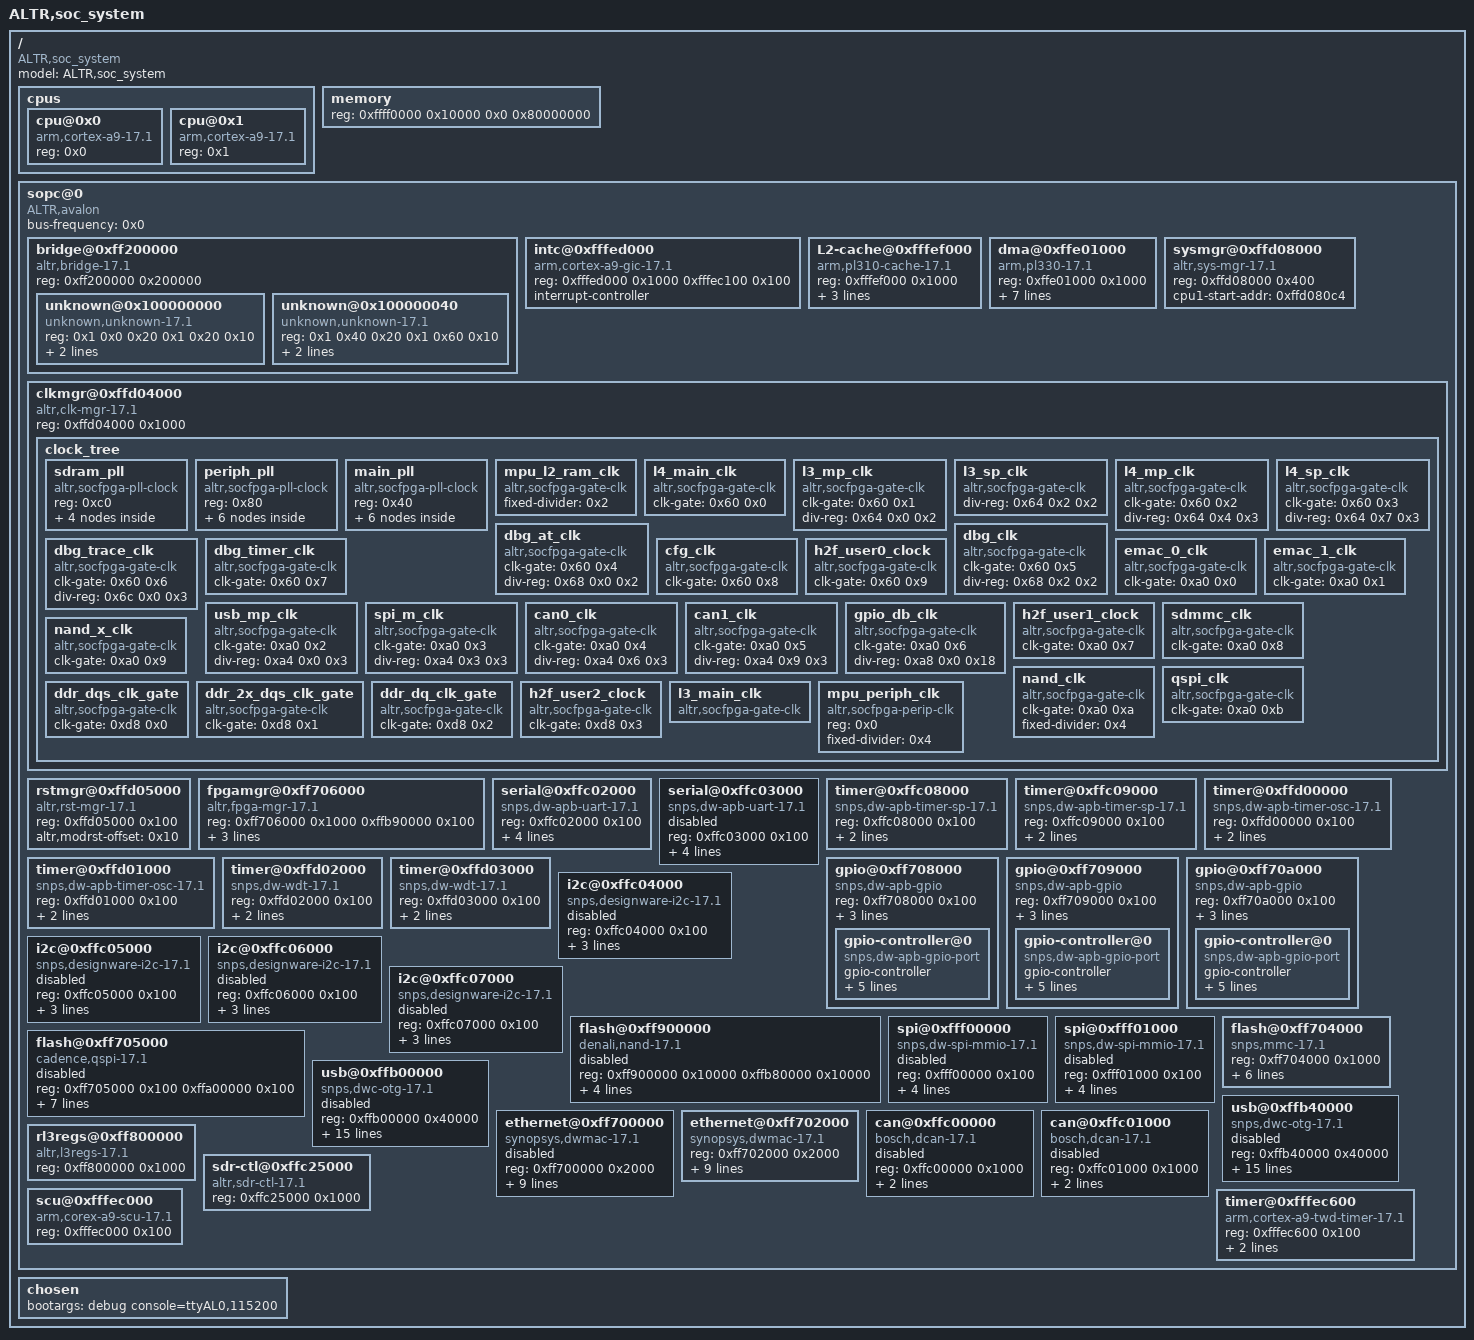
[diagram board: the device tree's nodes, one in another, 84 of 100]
/dts-v1/;

/ {
	model = "ALTR,soc_system";
	compatible = "ALTR,soc_system";
	#address-cells = <0x1>;
	#size-cells = <0x1>;

	cpus {
		#address-cells = <0x1>;
		#size-cells = <0x0>;

		cpu@0x0 {
			device_type = "cpu";
			compatible = "arm,cortex-a9-17.1", "arm,cortex-a9";
			reg = <0x0>;
		};

		cpu@0x1 {
			device_type = "cpu";
			compatible = "arm,cortex-a9-17.1", "arm,cortex-a9";
			reg = <0x1>;
		};
	};

	memory {
		device_type = "memory";
		reg = <0xffff0000 0x10000 0x0 0x80000000>;
	};

	sopc@0 {
		device_type = "soc";
		ranges;
		#address-cells = <0x1>;
		#size-cells = <0x1>;
		compatible = "ALTR,avalon", "simple-bus";
		bus-frequency = <0x0>;

		bridge@0xff200000 {
			compatible = "altr,bridge-17.1", "simple-bus";
			reg = <0xff200000 0x200000>;
			#address-cells = <0x2>;
			#size-cells = <0x1>;
			ranges = <0x1 0x0 0xff200000 0x20 0x1 0x40 0xff200040 0x20 0x1 0x20 0xff200020 0x10 0x1 0x60 0xff200060 0x10>;

			unknown@0x100000000 {
				compatible = "unknown,unknown-17.1";
				reg = <0x1 0x0 0x20 0x1 0x20 0x10>;
				reg-names = "CSR", "Descriptor_Slave";
				interrupt-parent = <0x1>;
				interrupts = <0x0 0x29 0x4 0x0 0x49 0x4>;
				interrupt-names = "csr_irq", "csr_irq";
			};

			unknown@0x100000040 {
				compatible = "unknown,unknown-17.1";
				reg = <0x1 0x40 0x20 0x1 0x60 0x10>;
				reg-names = "CSR", "Descriptor_Slave";
				interrupt-parent = <0x1>;
				interrupts = <0x0 0x28 0x4 0x0 0x48 0x4>;
				interrupt-names = "csr_irq", "csr_irq";
			};
		};

		intc@0xfffed000 {
			compatible = "arm,cortex-a9-gic-17.1", "arm,cortex-a9-gic";
			reg = <0xfffed000 0x1000 0xfffec100 0x100>;
			reg-names = "axi_slave0", "axi_slave1";
			interrupt-controller;
			#interrupt-cells = <0x3>;
			linux,phandle = <0x1>;
			phandle = <0x1>;
		};

		L2-cache@0xfffef000 {
			compatible = "arm,pl310-cache-17.1", "arm,pl310-cache";
			reg = <0xfffef000 0x1000>;
			interrupt-parent = <0x1>;
			interrupts = <0x0 0x26 0x4>;
			cache-level = <0x2>;
		};

		dma@0xffe01000 {
			compatible = "arm,pl330-17.1", "arm,pl330", "arm,primecell";
			reg = <0xffe01000 0x1000>;
			interrupt-parent = <0x1>;
			interrupts = <0x0 0x68 0x4>;
			#dma-cells = <0x1>;
			#dma-channels = <0x8>;
			#dma-requests = <0x20>;
			clock-names = "apb_pclk";
			copy-align = <0x3>;
			nr-irqs = <0x9>;
			nr-valid-peri = <0x9>;
		};

		sysmgr@0xffd08000 {
			compatible = "altr,sys-mgr-17.1", "altr,sys-mgr", "syscon";
			reg = <0xffd08000 0x400>;
			cpu1-start-addr = <0xffd080c4>;
		};

		clkmgr@0xffd04000 {
			compatible = "altr,clk-mgr-17.1", "altr,clk-mgr";
			reg = <0xffd04000 0x1000>;

			clock_tree {
				#size-cells = <0x0>;
				#address-cells = <0x1>;

				sdram_pll {
					compatible = "altr,socfpga-pll-clock";
					reg = <0xc0>;
					#clock-cells = <0x0>;
					#address-cells = <0x1>;
					#size-cells = <0x0>;

					ddr_dqs_clk {
						compatible = "altr,socfpga-perip-clk";
						reg = <0xc8>;
						#clock-cells = <0x0>;
					};

					ddr_2x_dqs_clk {
						compatible = "altr,socfpga-perip-clk";
						reg = <0xcc>;
						#clock-cells = <0x0>;
					};

					ddr_dq_clk {
						compatible = "altr,socfpga-perip-clk";
						reg = <0xd0>;
						#clock-cells = <0x0>;
					};

					s2f_usr2_clk {
						compatible = "altr,socfpga-perip-clk";
						reg = <0xd4>;
						#clock-cells = <0x0>;
					};
				};

				periph_pll {
					compatible = "altr,socfpga-pll-clock";
					reg = <0x80>;
					#clock-cells = <0x0>;
					#address-cells = <0x1>;
					#size-cells = <0x0>;

					per_nand_mmc_clk {
						compatible = "altr,socfpga-perip-clk";
						reg = <0x94>;
						#clock-cells = <0x0>;
					};

					per_base_clk {
						compatible = "altr,socfpga-perip-clk";
						reg = <0x98>;
						#clock-cells = <0x0>;
					};

					per_qspi_clk {
						compatible = "altr,socfpga-perip-clk";
						reg = <0x90>;
						#clock-cells = <0x0>;
					};

					s2f_usr1_clk {
						compatible = "altr,socfpga-perip-clk";
						reg = <0x9c>;
						#clock-cells = <0x0>;
					};

					emac0_clk {
						compatible = "altr,socfpga-perip-clk";
						reg = <0x88>;
						#clock-cells = <0x0>;
					};

					emac1_clk {
						compatible = "altr,socfpga-perip-clk";
						reg = <0x8c>;
						#clock-cells = <0x0>;
					};
				};

				main_pll {
					compatible = "altr,socfpga-pll-clock";
					reg = <0x40>;
					#clock-cells = <0x0>;
					#address-cells = <0x1>;
					#size-cells = <0x0>;

					cfg_s2f_usr0_clk {
						compatible = "altr,socfpga-perip-clk";
						reg = <0x5c>;
						#clock-cells = <0x0>;
					};

					main_qspi_clk {
						compatible = "altr,socfpga-perip-clk";
						reg = <0x54>;
						#clock-cells = <0x0>;
					};

					dbg_base_clk {
						compatible = "altr,socfpga-perip-clk";
						reg = <0x50>;
						#clock-cells = <0x0>;
						div-reg = <0xe8 0x0 0x9>;
					};

					mpuclk {
						compatible = "altr,socfpga-perip-clk";
						reg = <0x48>;
						#clock-cells = <0x0>;
						div-reg = <0xe0 0x0 0x9>;
					};

					mainclk {
						compatible = "altr,socfpga-perip-clk";
						reg = <0x4c>;
						#clock-cells = <0x0>;
						div-reg = <0xe4 0x0 0x9>;
					};

					main_nand_sdmmc_clk {
						compatible = "altr,socfpga-perip-clk";
						reg = <0x58>;
						#clock-cells = <0x0>;
					};
				};

				mpu_l2_ram_clk {
					compatible = "altr,socfpga-gate-clk";
					#clock-cells = <0x0>;
					fixed-divider = <0x2>;
				};

				l4_main_clk {
					compatible = "altr,socfpga-gate-clk";
					#clock-cells = <0x0>;
					clk-gate = <0x60 0x0>;
				};

				l3_mp_clk {
					compatible = "altr,socfpga-gate-clk";
					#clock-cells = <0x0>;
					clk-gate = <0x60 0x1>;
					div-reg = <0x64 0x0 0x2>;
				};

				l3_sp_clk {
					compatible = "altr,socfpga-gate-clk";
					#clock-cells = <0x0>;
					div-reg = <0x64 0x2 0x2>;
				};

				l4_mp_clk {
					compatible = "altr,socfpga-gate-clk";
					#clock-cells = <0x0>;
					clk-gate = <0x60 0x2>;
					div-reg = <0x64 0x4 0x3>;
				};

				l4_sp_clk {
					compatible = "altr,socfpga-gate-clk";
					#clock-cells = <0x0>;
					clk-gate = <0x60 0x3>;
					div-reg = <0x64 0x7 0x3>;
				};

				dbg_at_clk {
					compatible = "altr,socfpga-gate-clk";
					#clock-cells = <0x0>;
					clk-gate = <0x60 0x4>;
					div-reg = <0x68 0x0 0x2>;
				};

				dbg_clk {
					compatible = "altr,socfpga-gate-clk";
					#clock-cells = <0x0>;
					clk-gate = <0x60 0x5>;
					div-reg = <0x68 0x2 0x2>;
				};

				dbg_trace_clk {
					compatible = "altr,socfpga-gate-clk";
					#clock-cells = <0x0>;
					clk-gate = <0x60 0x6>;
					div-reg = <0x6c 0x0 0x3>;
				};

				dbg_timer_clk {
					compatible = "altr,socfpga-gate-clk";
					#clock-cells = <0x0>;
					clk-gate = <0x60 0x7>;
				};

				cfg_clk {
					compatible = "altr,socfpga-gate-clk";
					#clock-cells = <0x0>;
					clk-gate = <0x60 0x8>;
				};

				h2f_user0_clock {
					compatible = "altr,socfpga-gate-clk";
					#clock-cells = <0x0>;
					clk-gate = <0x60 0x9>;
				};

				emac_0_clk {
					compatible = "altr,socfpga-gate-clk";
					#clock-cells = <0x0>;
					clk-gate = <0xa0 0x0>;
				};

				emac_1_clk {
					compatible = "altr,socfpga-gate-clk";
					#clock-cells = <0x0>;
					clk-gate = <0xa0 0x1>;
				};

				usb_mp_clk {
					compatible = "altr,socfpga-gate-clk";
					#clock-cells = <0x0>;
					clk-gate = <0xa0 0x2>;
					div-reg = <0xa4 0x0 0x3>;
				};

				spi_m_clk {
					compatible = "altr,socfpga-gate-clk";
					#clock-cells = <0x0>;
					clk-gate = <0xa0 0x3>;
					div-reg = <0xa4 0x3 0x3>;
				};

				can0_clk {
					compatible = "altr,socfpga-gate-clk";
					#clock-cells = <0x0>;
					clk-gate = <0xa0 0x4>;
					div-reg = <0xa4 0x6 0x3>;
				};

				can1_clk {
					compatible = "altr,socfpga-gate-clk";
					#clock-cells = <0x0>;
					clk-gate = <0xa0 0x5>;
					div-reg = <0xa4 0x9 0x3>;
				};

				gpio_db_clk {
					compatible = "altr,socfpga-gate-clk";
					#clock-cells = <0x0>;
					clk-gate = <0xa0 0x6>;
					div-reg = <0xa8 0x0 0x18>;
				};

				h2f_user1_clock {
					compatible = "altr,socfpga-gate-clk";
					#clock-cells = <0x0>;
					clk-gate = <0xa0 0x7>;
				};

				sdmmc_clk {
					compatible = "altr,socfpga-gate-clk";
					#clock-cells = <0x0>;
					clk-gate = <0xa0 0x8>;
				};

				nand_x_clk {
					compatible = "altr,socfpga-gate-clk";
					#clock-cells = <0x0>;
					clk-gate = <0xa0 0x9>;
				};

				nand_clk {
					compatible = "altr,socfpga-gate-clk";
					#clock-cells = <0x0>;
					clk-gate = <0xa0 0xa>;
					fixed-divider = <0x4>;
				};

				qspi_clk {
					compatible = "altr,socfpga-gate-clk";
					#clock-cells = <0x0>;
					clk-gate = <0xa0 0xb>;
				};

				ddr_dqs_clk_gate {
					compatible = "altr,socfpga-gate-clk";
					#clock-cells = <0x0>;
					clk-gate = <0xd8 0x0>;
				};

				ddr_2x_dqs_clk_gate {
					compatible = "altr,socfpga-gate-clk";
					#clock-cells = <0x0>;
					clk-gate = <0xd8 0x1>;
				};

				ddr_dq_clk_gate {
					compatible = "altr,socfpga-gate-clk";
					#clock-cells = <0x0>;
					clk-gate = <0xd8 0x2>;
				};

				h2f_user2_clock {
					compatible = "altr,socfpga-gate-clk";
					#clock-cells = <0x0>;
					clk-gate = <0xd8 0x3>;
				};

				l3_main_clk {
					compatible = "altr,socfpga-gate-clk";
					#clock-cells = <0x0>;
				};

				mpu_periph_clk {
					compatible = "altr,socfpga-perip-clk";
					#clock-cells = <0x0>;
					reg = <0x0>;
					fixed-divider = <0x4>;
				};
			};
		};

		rstmgr@0xffd05000 {
			compatible = "altr,rst-mgr-17.1", "altr,rst-mgr", "syscon";
			reg = <0xffd05000 0x100>;
			#reset-cells = <0x1>;
			altr,modrst-offset = <0x10>;
		};

		fpgamgr@0xff706000 {
			compatible = "altr,fpga-mgr-17.1", "altr,fpga-mgr", "altr,socfpga-fpga-mgr";
			reg = <0xff706000 0x1000 0xffb90000 0x100>;
			reg-names = "axi_slave0", "axi_slave1";
			interrupt-parent = <0x1>;
			interrupts = <0x0 0xaf 0x4>;
			transport = "mmio";
		};

		serial@0xffc02000 {
			compatible = "snps,dw-apb-uart-17.1", "snps,dw-apb-uart";
			reg = <0xffc02000 0x100>;
			interrupt-parent = <0x1>;
			interrupts = <0x0 0xa2 0x4>;
			reg-io-width = <0x4>;
			reg-shift = <0x2>;
			status = "okay";
		};

		serial@0xffc03000 {
			compatible = "snps,dw-apb-uart-17.1", "snps,dw-apb-uart";
			reg = <0xffc03000 0x100>;
			interrupt-parent = <0x1>;
			interrupts = <0x0 0xa3 0x4>;
			reg-io-width = <0x4>;
			reg-shift = <0x2>;
			status = "disabled";
		};

		timer@0xffc08000 {
			compatible = "snps,dw-apb-timer-sp-17.1", "snps,dw-apb-timer-sp";
			reg = <0xffc08000 0x100>;
			interrupt-parent = <0x1>;
			interrupts = <0x0 0xa7 0x4>;
			clock-names = "timer";
		};

		timer@0xffc09000 {
			compatible = "snps,dw-apb-timer-sp-17.1", "snps,dw-apb-timer-sp";
			reg = <0xffc09000 0x100>;
			interrupt-parent = <0x1>;
			interrupts = <0x0 0xa8 0x4>;
			clock-names = "timer";
		};

		timer@0xffd00000 {
			compatible = "snps,dw-apb-timer-osc-17.1", "snps,dw-apb-timer-osc";
			reg = <0xffd00000 0x100>;
			interrupt-parent = <0x1>;
			interrupts = <0x0 0xa9 0x4>;
			clock-names = "timer";
		};

		timer@0xffd01000 {
			compatible = "snps,dw-apb-timer-osc-17.1", "snps,dw-apb-timer-osc";
			reg = <0xffd01000 0x100>;
			interrupt-parent = <0x1>;
			interrupts = <0x0 0xaa 0x4>;
			clock-names = "timer";
		};

		timer@0xffd02000 {
			compatible = "snps,dw-wdt-17.1", "snps,dw-wdt";
			reg = <0xffd02000 0x100>;
			interrupt-parent = <0x1>;
			interrupts = <0x0 0xab 0x4>;
			clock-names = "timer";
		};

		timer@0xffd03000 {
			compatible = "snps,dw-wdt-17.1", "snps,dw-wdt";
			reg = <0xffd03000 0x100>;
			interrupt-parent = <0x1>;
			interrupts = <0x0 0xac 0x4>;
			clock-names = "timer";
		};

		gpio@0xff708000 {
			compatible = "snps,dw-apb-gpio", "snps,dw-gpio-17.1", "snps,dw-gpio";
			reg = <0xff708000 0x100>;
			interrupt-parent = <0x1>;
			interrupts = <0x0 0xa4 0x4>;
			#gpio-cells = <0x2>;
			gpio-controller;
			#address-cells = <0x1>;
			#size-cells = <0x0>;

			gpio-controller@0 {
				compatible = "snps,dw-apb-gpio-port";
				gpio-controller;
				#gpio-cells = <0x2>;
				snps,nr-gpios = <0x1d>;
				reg = <0x0>;
				interrupt-controller;
				#interrupt-cells = <0x2>;
				interrupts = <0x0 0xa4 0x4>;
				interrupt-parent = <0x1>;
			};
		};

		gpio@0xff709000 {
			compatible = "snps,dw-apb-gpio", "snps,dw-gpio-17.1", "snps,dw-gpio";
			reg = <0xff709000 0x100>;
			interrupt-parent = <0x1>;
			interrupts = <0x0 0xa5 0x4>;
			#gpio-cells = <0x2>;
			gpio-controller;
			#address-cells = <0x1>;
			#size-cells = <0x0>;

			gpio-controller@0 {
				compatible = "snps,dw-apb-gpio-port";
				gpio-controller;
				#gpio-cells = <0x2>;
				snps,nr-gpios = <0x1d>;
				reg = <0x0>;
				interrupt-controller;
				#interrupt-cells = <0x2>;
				interrupts = <0x0 0xa5 0x4>;
				interrupt-parent = <0x1>;
			};
		};

		gpio@0xff70a000 {
			compatible = "snps,dw-apb-gpio", "snps,dw-gpio-17.1", "snps,dw-gpio";
			reg = <0xff70a000 0x100>;
			interrupt-parent = <0x1>;
			interrupts = <0x0 0xa6 0x4>;
			#gpio-cells = <0x2>;
			gpio-controller;
			#address-cells = <0x1>;
			#size-cells = <0x0>;

			gpio-controller@0 {
				compatible = "snps,dw-apb-gpio-port";
				gpio-controller;
				#gpio-cells = <0x2>;
				snps,nr-gpios = <0x1b>;
				reg = <0x0>;
				interrupt-controller;
				#interrupt-cells = <0x2>;
				interrupts = <0x0 0xa6 0x4>;
				interrupt-parent = <0x1>;
			};
		};

		i2c@0xffc04000 {
			compatible = "snps,designware-i2c-17.1", "snps,designware-i2c";
			reg = <0xffc04000 0x100>;
			interrupt-parent = <0x1>;
			interrupts = <0x0 0x9e 0x4>;
			emptyfifo_hold_master = <0x1>;
			status = "disabled";
		};

		i2c@0xffc05000 {
			compatible = "snps,designware-i2c-17.1", "snps,designware-i2c";
			reg = <0xffc05000 0x100>;
			interrupt-parent = <0x1>;
			interrupts = <0x0 0x9f 0x4>;
			emptyfifo_hold_master = <0x1>;
			status = "disabled";
		};

		i2c@0xffc06000 {
			compatible = "snps,designware-i2c-17.1", "snps,designware-i2c";
			reg = <0xffc06000 0x100>;
			interrupt-parent = <0x1>;
			interrupts = <0x0 0xa0 0x4>;
			emptyfifo_hold_master = <0x1>;
			status = "disabled";
		};

		i2c@0xffc07000 {
			compatible = "snps,designware-i2c-17.1", "snps,designware-i2c";
			reg = <0xffc07000 0x100>;
			interrupt-parent = <0x1>;
			interrupts = <0x0 0xa1 0x4>;
			emptyfifo_hold_master = <0x1>;
			status = "disabled";
		};

		flash@0xff900000 {
			compatible = "denali,nand-17.1", "denali,denali-nand-dt";
			reg = <0xff900000 0x10000 0xffb80000 0x10000>;
			reg-names = "nand_data", "denali_reg";
			interrupt-parent = <0x1>;
			interrupts = <0x0 0x90 0x4>;
			#address-cells = <0x1>;
			#size-cells = <0x1>;
			status = "disabled";
			bank-width = <0x2>;
			device-width = <0x1>;
		};

		spi@0xfff00000 {
			compatible = "snps,dw-spi-mmio-17.1", "snps,dw-spi-mmio", "snps,dw-apb-ssi";
			reg = <0xfff00000 0x100>;
			interrupt-parent = <0x1>;
			interrupts = <0x0 0x9a 0x4>;
			#address-cells = <0x1>;
			#size-cells = <0x0>;
			bus-num = <0x0>;
			num-chipselect = <0x4>;
			status = "disabled";
		};

		spi@0xfff01000 {
			compatible = "snps,dw-spi-mmio-17.1", "snps,dw-spi-mmio", "snps,dw-apb-ssi";
			reg = <0xfff01000 0x100>;
			interrupt-parent = <0x1>;
			interrupts = <0x0 0x9b 0x4>;
			#address-cells = <0x1>;
			#size-cells = <0x0>;
			bus-num = <0x0>;
			num-chipselect = <0x4>;
			status = "disabled";
		};

		flash@0xff705000 {
			compatible = "cadence,qspi-17.1", "cadence,qspi", "cdns,qspi-nor";
			reg = <0xff705000 0x100 0xffa00000 0x100>;
			reg-names = "axi_slave0", "axi_slave1";
			interrupt-parent = <0x1>;
			interrupts = <0x0 0x97 0x4>;
			bus-num = <0x2>;
			fifo-depth = <0x80>;
			num-chipselect = <0x4>;
			status = "disabled";
			bank-width = <0x2>;
			device-width = <0x1>;
		};

		flash@0xff704000 {
			compatible = "snps,mmc-17.1", "altr,socfpga-dw-mshc";
			reg = <0xff704000 0x1000>;
			interrupt-parent = <0x1>;
			interrupts = <0x0 0x8b 0x4>;
			fifo-depth = <0x400>;
			num-slots = <0x1>;
			status = "okay";
			bank-width = <0x2>;
			device-width = <0x1>;
		};

		usb@0xffb00000 {
			compatible = "snps,dwc-otg-17.1", "snps,dwc-otg", "snps,dwc2";
			reg = <0xffb00000 0x40000>;
			interrupt-parent = <0x1>;
			interrupts = <0x0 0x7d 0x4>;
			clock-names = "otg";
			dev-nperio-tx-fifo-size = <0x1000>;
			dev-perio-tx-fifo-size = "<512 512 512 512 512 512 512 512 512 512 512 512 512 512 512>";
			dev-rx-fifo-size = <0x200>;
			dev-tx-fifo-size = "<512 512 512 512 512 512 512 512 512 512 512 512 512 512 512>";
			dma-mask = <0xfffffff>;
			enable-dynamic-fifo = <0x1>;
			host-nperio-tx-fifo-size = <0xa00>;
			host-perio-tx-fifo-size = <0xa00>;
			host-rx-fifo-size = <0xa00>;
			phy-names = "usb2-phy";
			status = "disabled";
			ulpi-ddr = <0x0>;
			voltage-switch = <0x0>;
		};

		usb@0xffb40000 {
			compatible = "snps,dwc-otg-17.1", "snps,dwc-otg", "snps,dwc2";
			reg = <0xffb40000 0x40000>;
			interrupt-parent = <0x1>;
			interrupts = <0x0 0x80 0x4>;
			clock-names = "otg";
			dev-nperio-tx-fifo-size = <0x1000>;
			dev-perio-tx-fifo-size = "<512 512 512 512 512 512 512 512 512 512 512 512 512 512 512>";
			dev-rx-fifo-size = <0x200>;
			dev-tx-fifo-size = "<512 512 512 512 512 512 512 512 512 512 512 512 512 512 512>";
			dma-mask = <0xfffffff>;
			enable-dynamic-fifo = <0x1>;
			host-nperio-tx-fifo-size = <0xa00>;
			host-perio-tx-fifo-size = <0xa00>;
			host-rx-fifo-size = <0xa00>;
			phy-names = "usb2-phy";
			status = "disabled";
			ulpi-ddr = <0x0>;
			voltage-switch = <0x0>;
		};

		ethernet@0xff700000 {
			compatible = "synopsys,dwmac-17.1", "altr,socfpga-stmmac", "snps,dwmac-3.70a", "snps,dwmac";
			reg = <0xff700000 0x2000>;
			interrupt-parent = <0x1>;
			interrupts = <0x0 0x73 0x4>;
			clock-names = "stmmaceth";
			interrupt-names = "macirq";
			rx-fifo-depth = <0x1000>;
			snps,multicast-filter-bins = <0x100>;
			snps,perfect-filter-entries = <0x80>;
			status = "disabled";
			tx-fifo-depth = <0x1000>;
			address-bits = <0x30>;
			max-frame-size = <0x5ee>;
			local-mac-address = [00 00 00 00 00 00];
		};

		ethernet@0xff702000 {
			compatible = "synopsys,dwmac-17.1", "altr,socfpga-stmmac", "snps,dwmac-3.70a", "snps,dwmac";
			reg = <0xff702000 0x2000>;
			interrupt-parent = <0x1>;
			interrupts = <0x0 0x78 0x4>;
			clock-names = "stmmaceth";
			interrupt-names = "macirq";
			rx-fifo-depth = <0x1000>;
			snps,multicast-filter-bins = <0x100>;
			snps,perfect-filter-entries = <0x80>;
			status = "okay";
			tx-fifo-depth = <0x1000>;
			address-bits = <0x30>;
			max-frame-size = <0x5ee>;
			local-mac-address = [00 00 00 00 00 00];
		};

		can@0xffc00000 {
			compatible = "bosch,dcan-17.1", "bosch,d_can";
			reg = <0xffc00000 0x1000>;
			interrupt-parent = <0x1>;
			interrupts = <0x0 0x83 0x4 0x0 0x84 0x4>;
			interrupt-names = "interrupt_sender0", "interrupt_sender1";
			status = "disabled";
		};

		can@0xffc01000 {
			compatible = "bosch,dcan-17.1", "bosch,d_can";
			reg = <0xffc01000 0x1000>;
			interrupt-parent = <0x1>;
			interrupts = <0x0 0x87 0x4 0x0 0x88 0x4>;
			interrupt-names = "interrupt_sender0", "interrupt_sender1";
			status = "disabled";
		};

		rl3regs@0xff800000 {
			compatible = "altr,l3regs-17.1", "altr,l3regs", "syscon";
			reg = <0xff800000 0x1000>;
		};

		sdr-ctl@0xffc25000 {
			compatible = "altr,sdr-ctl-17.1", "altr,sdr-ctl", "syscon";
			reg = <0xffc25000 0x1000>;
		};

		timer@0xfffec600 {
			compatible = "arm,cortex-a9-twd-timer-17.1", "arm,cortex-a9-twd-timer";
			reg = <0xfffec600 0x100>;
			interrupt-parent = <0x1>;
			interrupts = <0x1 0xd 0xf04>;
		};

		scu@0xfffec000 {
			compatible = "arm,corex-a9-scu-17.1", "arm,cortex-a9-scu";
			reg = <0xfffec000 0x100>;
		};
	};

	chosen {
		bootargs = "debug console=ttyAL0,115200";
	};
};
